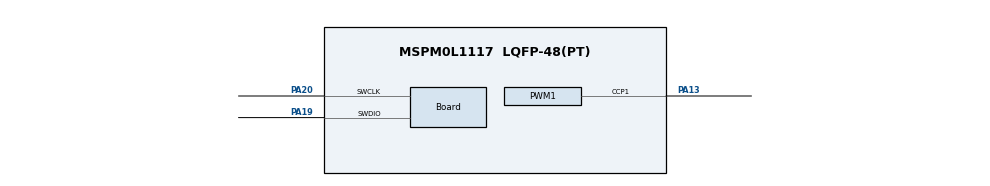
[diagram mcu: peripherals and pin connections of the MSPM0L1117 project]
//@cliArgs --device "MSPM0L111X" --package "LQFP-48(PT)" --part "Default"
//@v2CliArgs --device "MSPM0L1117" --package "LQFP-48(PT)"
// @cliArgs --board /ti/boards/LP_MSPM0L1117 --rtos nortos

/**
 * Import the modules used in this configuration.
 */
const GPIO  = scripting.addModule("/ti/driverlib/GPIO", {}, false);
const GPIO1 = GPIO.addInstance();
const PWM   = scripting.addModule("/ti/driverlib/PWM", {}, false);
const PWM1  = PWM.addInstance();

/**
 * Write custom configuration values to the imported modules.
 */
GPIO1.$name                   = "LED";
GPIO1.port                    = "PORTA";
GPIO1.associatedPins[0].$name = "LED0";

const Board                       = scripting.addModule("/ti/driverlib/Board", {}, false);
Board.peripheral.$assign          = "DEBUGSS";
Board.peripheral.swclkPin.$assign = "PA20";
Board.peripheral.swdioPin.$assign = "PA19";

PWM1.$name                      = "PWM_0";
PWM1.clockPrescale              = 256;
PWM1.timerCount                 = 2000;
PWM1.timerStartTimer            = true;
PWM1.interrupts                 = ["CC0_DN_EVENT","LOAD_EVENT"];
PWM1.ccIndex                    = [1];
PWM1.peripheral.$assign         = "TIMG0";
PWM1.peripheral.ccp1Pin.$assign = "PA13";
PWM1.PWM_CHANNEL_1.$name        = "ti_driverlib_pwm_PWMTimerCC0";
PWM1.PWM_CHANNEL_1.dutyCycle    = 10;

const SYSCTL              = scripting.addModule("/ti/driverlib/SYSCTL", {}, false);
SYSCTL.peripheral.$assign = "SYSCTL";

const ProjectConfig              = scripting.addModule("/ti/project_config/ProjectConfig", {}, false);
ProjectConfig.migrationCondition = true;
